# wl_phy_tx_secure register map
Vendor: Texas Instruments
Registers are 32-bit, access per field, reset 0x0 unless marked. A register's access mark holds for its fields unless they carry their own. Offsets are as the file gives them; [hi:lo] are bit positions; {n}, {i} and the like mark numbered series; <NAME> marks a mode.

## wl_phy_tx_secure (part 2 of 2)
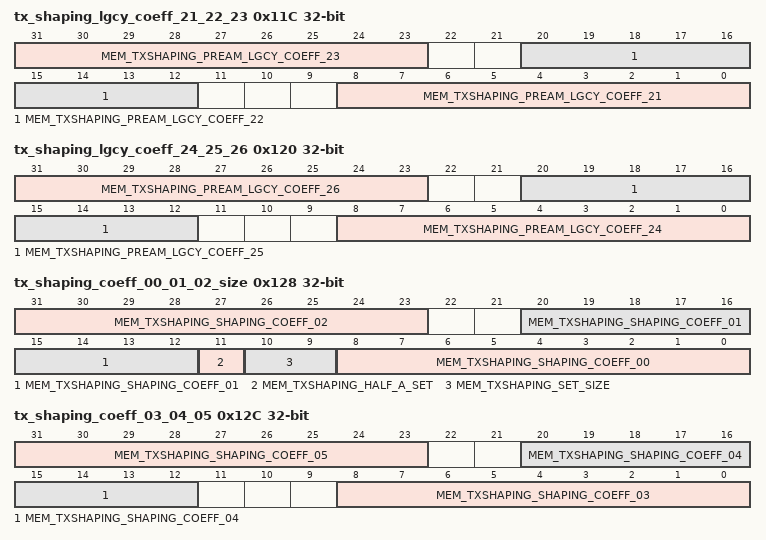
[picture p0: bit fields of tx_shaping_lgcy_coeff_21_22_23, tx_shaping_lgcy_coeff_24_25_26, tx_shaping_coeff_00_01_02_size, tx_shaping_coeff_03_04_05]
0x11C tx_shaping_lgcy_coeff_21_22_23 reset not defined — Part of the 28 coeffs for the legacy part of the preamble.
  [31:23] MEM_TXSHAPING_PREAM_LGCY_COEFF_23 rw — Part of the 28 coeffs for the legacy part of the preamble. <1.8u>
  [20:12] MEM_TXSHAPING_PREAM_LGCY_COEFF_22 rw — Part of the 28 coeffs for the legacy part of the preamble. <1.8u>
  [8:0] MEM_TXSHAPING_PREAM_LGCY_COEFF_21 rw — Part of the 28 coeffs for the legacy part of the preamble. <1.8u>
0x120 tx_shaping_lgcy_coeff_24_25_26 reset not defined — Part of the 28 coeffs for the legacy part of the preamble.
  [31:23] MEM_TXSHAPING_PREAM_LGCY_COEFF_26 rw — Part of the 28 coeffs for the legacy part of the preamble. <1.8u>
  [20:12] MEM_TXSHAPING_PREAM_LGCY_COEFF_25 rw — Part of the 28 coeffs for the legacy part of the preamble. <1.8u>
  [8:0] MEM_TXSHAPING_PREAM_LGCY_COEFF_24 rw — Part of the 28 coeffs for the legacy part of the preamble. <1.8u>
0x124 tx_shaping_lgcy_coeff_27 reset 0x27339 — Part of the 28 coeffs for the legacy part of the preamble.
  [8:0] MEM_TXSHAPING_PREAM_LGCY_COEFF_27 rw — Part of the 28 coeffs for the legacy part of the preamble. <1.8u>
0x128 tx_shaping_coeff_00_01_02_size — Part of the 62 coeffs for the shaping function. <1.8u>
  [31:23] MEM_TXSHAPING_SHAPING_COEFF_02 rw — Part of the 62 coeffs for the shaping function. <1.8u>
  [20:12] MEM_TXSHAPING_SHAPING_COEFF_01 rw — Part of the 62 coeffs for the shaping function. <1.8u>
  [11] MEM_TXSHAPING_HALF_A_SET rw — Half a Set option: 0: Disabled. 1: Enabled.
  [10:9] MEM_TXSHAPING_SET_SIZE rw — Set Size options: 0: 0 coefficients, Bypass Shaping module. 1: 18 coefficients. 2: 32 coefficients. 3: 62 coefficients.
  [8:0] MEM_TXSHAPING_SHAPING_COEFF_00 rw — Part of the 62 coeffs for the shaping function. <1.8u>
0x12C tx_shaping_coeff_03_04_05 — Part of the 62 coeffs for the shaping function. <1.8u>
  [31:23] MEM_TXSHAPING_SHAPING_COEFF_05 rw — Part of the 62 coeffs for the shaping function. <1.8u>
  [20:12] MEM_TXSHAPING_SHAPING_COEFF_04 rw — Part of the 62 coeffs for the shaping function. <1.8u>
  [8:0] MEM_TXSHAPING_SHAPING_COEFF_03 rw — Part of the 62 coeffs for the shaping function. <1.8u>
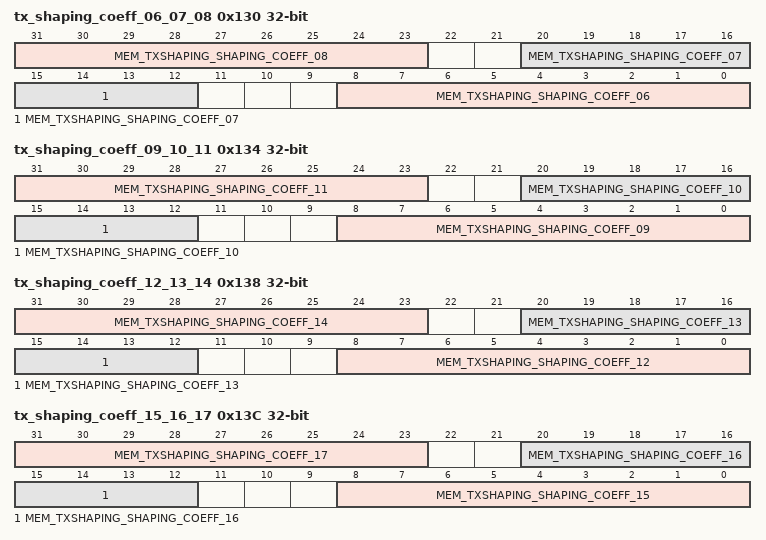
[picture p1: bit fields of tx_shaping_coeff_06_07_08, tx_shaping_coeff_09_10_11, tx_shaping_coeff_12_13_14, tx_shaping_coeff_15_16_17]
0x130 tx_shaping_coeff_06_07_08 — Part of the 62 coeffs for the shaping function. <1.8u>
  [31:23] MEM_TXSHAPING_SHAPING_COEFF_08 rw — Part of the 62 coeffs for the shaping function. <1.8u>
  [20:12] MEM_TXSHAPING_SHAPING_COEFF_07 rw — Part of the 62 coeffs for the shaping function. <1.8u>
  [8:0] MEM_TXSHAPING_SHAPING_COEFF_06 rw — Part of the 62 coeffs for the shaping function. <1.8u>
0x134 tx_shaping_coeff_09_10_11 — Part of the 62 coeffs for the shaping function. <1.8u>
  [31:23] MEM_TXSHAPING_SHAPING_COEFF_11 rw — Part of the 62 coeffs for the shaping function. <1.8u>
  [20:12] MEM_TXSHAPING_SHAPING_COEFF_10 rw — Part of the 62 coeffs for the shaping function. <1.8u>
  [8:0] MEM_TXSHAPING_SHAPING_COEFF_09 rw — Part of the 62 coeffs for the shaping function. <1.8u>
0x138 tx_shaping_coeff_12_13_14 — Part of the 62 coeffs for the shaping function. <1.8u>
  [31:23] MEM_TXSHAPING_SHAPING_COEFF_14 rw — Part of the 62 coeffs for the shaping function. <1.8u>
  [20:12] MEM_TXSHAPING_SHAPING_COEFF_13 rw — Part of the 62 coeffs for the shaping function. <1.8u>
  [8:0] MEM_TXSHAPING_SHAPING_COEFF_12 rw — Part of the 62 coeffs for the shaping function. <1.8u>
0x13C tx_shaping_coeff_15_16_17 — Part of the 62 coeffs for the shaping function. <1.8u>
  [31:23] MEM_TXSHAPING_SHAPING_COEFF_17 rw — Part of the 62 coeffs for the shaping function. <1.8u>
  [20:12] MEM_TXSHAPING_SHAPING_COEFF_16 rw — Part of the 62 coeffs for the shaping function. <1.8u>
  [8:0] MEM_TXSHAPING_SHAPING_COEFF_15 rw — Part of the 62 coeffs for the shaping function. <1.8u>
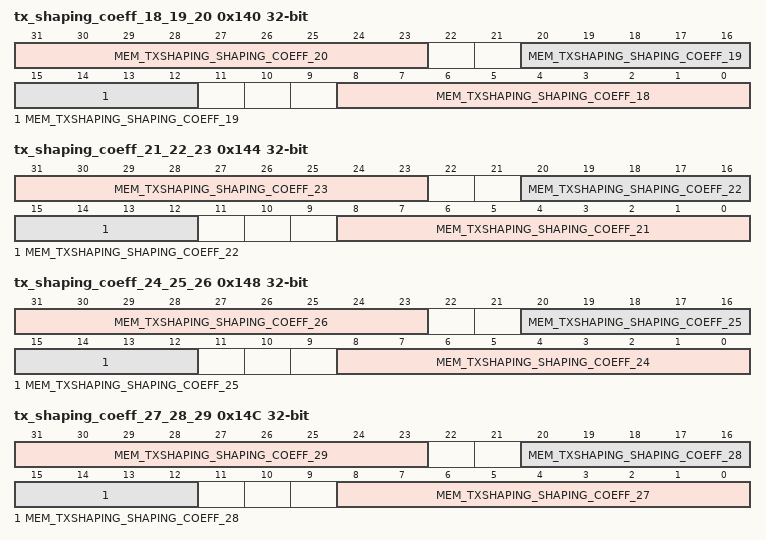
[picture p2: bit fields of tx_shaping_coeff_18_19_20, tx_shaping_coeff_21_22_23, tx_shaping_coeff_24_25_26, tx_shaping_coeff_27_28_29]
0x140 tx_shaping_coeff_18_19_20 — Part of the 62 coeffs for the shaping function. <1.8u>
  [31:23] MEM_TXSHAPING_SHAPING_COEFF_20 rw — Part of the 62 coeffs for the shaping function. <1.8u>
  [20:12] MEM_TXSHAPING_SHAPING_COEFF_19 rw — Part of the 62 coeffs for the shaping function. <1.8u>
  [8:0] MEM_TXSHAPING_SHAPING_COEFF_18 rw — Part of the 62 coeffs for the shaping function. <1.8u>
0x144 tx_shaping_coeff_21_22_23 — Part of the 62 coeffs for the shaping function. <1.8u>
  [31:23] MEM_TXSHAPING_SHAPING_COEFF_23 rw — Part of the 62 coeffs for the shaping function. <1.8u>
  [20:12] MEM_TXSHAPING_SHAPING_COEFF_22 rw — Part of the 62 coeffs for the shaping function. <1.8u>
  [8:0] MEM_TXSHAPING_SHAPING_COEFF_21 rw — Part of the 62 coeffs for the shaping function. <1.8u>
0x148 tx_shaping_coeff_24_25_26 — Part of the 62 coeffs for the shaping function. <1.8u>
  [31:23] MEM_TXSHAPING_SHAPING_COEFF_26 rw — Part of the 62 coeffs for the shaping function. <1.8u>
  [20:12] MEM_TXSHAPING_SHAPING_COEFF_25 rw — Part of the 62 coeffs for the shaping function. <1.8u>
  [8:0] MEM_TXSHAPING_SHAPING_COEFF_24 rw — Part of the 62 coeffs for the shaping function. <1.8u>
0x14C tx_shaping_coeff_27_28_29 — Part of the 62 coeffs for the shaping function. <1.8u>
  [31:23] MEM_TXSHAPING_SHAPING_COEFF_29 rw — Part of the 62 coeffs for the shaping function. <1.8u>
  [20:12] MEM_TXSHAPING_SHAPING_COEFF_28 rw — Part of the 62 coeffs for the shaping function. <1.8u>
  [8:0] MEM_TXSHAPING_SHAPING_COEFF_27 rw — Part of the 62 coeffs for the shaping function. <1.8u>
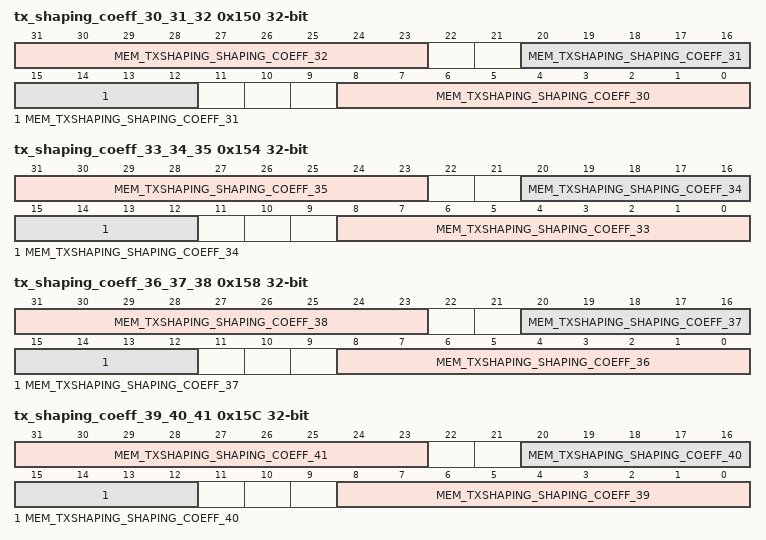
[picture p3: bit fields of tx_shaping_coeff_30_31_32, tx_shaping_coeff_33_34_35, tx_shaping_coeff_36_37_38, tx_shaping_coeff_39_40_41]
0x150 tx_shaping_coeff_30_31_32 — Part of the 62 coeffs for the shaping function. <1.8u>
  [31:23] MEM_TXSHAPING_SHAPING_COEFF_32 rw — Part of the 62 coeffs for the shaping function. <1.8u>
  [20:12] MEM_TXSHAPING_SHAPING_COEFF_31 rw — Part of the 62 coeffs for the shaping function. <1.8u>
  [8:0] MEM_TXSHAPING_SHAPING_COEFF_30 rw — Part of the 62 coeffs for the shaping function. <1.8u>
0x154 tx_shaping_coeff_33_34_35 — Part of the 62 coeffs for the shaping function. <1.8u>
  [31:23] MEM_TXSHAPING_SHAPING_COEFF_35 rw — Part of the 62 coeffs for the shaping function. <1.8u>
  [20:12] MEM_TXSHAPING_SHAPING_COEFF_34 rw — Part of the 62 coeffs for the shaping function. <1.8u>
  [8:0] MEM_TXSHAPING_SHAPING_COEFF_33 rw — Part of the 62 coeffs for the shaping function. <1.8u>
0x158 tx_shaping_coeff_36_37_38 — Part of the 62 coeffs for the shaping function. <1.8u>
  [31:23] MEM_TXSHAPING_SHAPING_COEFF_38 rw — Part of the 62 coeffs for the shaping function. <1.8u>
  [20:12] MEM_TXSHAPING_SHAPING_COEFF_37 rw — Part of the 62 coeffs for the shaping function. <1.8u>
  [8:0] MEM_TXSHAPING_SHAPING_COEFF_36 rw — Part of the 62 coeffs for the shaping function. <1.8u>
0x15C tx_shaping_coeff_39_40_41 — Part of the 62 coeffs for the shaping function. <1.8u>
  [31:23] MEM_TXSHAPING_SHAPING_COEFF_41 rw — Part of the 62 coeffs for the shaping function. <1.8u>
  [20:12] MEM_TXSHAPING_SHAPING_COEFF_40 rw — Part of the 62 coeffs for the shaping function. <1.8u>
  [8:0] MEM_TXSHAPING_SHAPING_COEFF_39 rw — Part of the 62 coeffs for the shaping function. <1.8u>
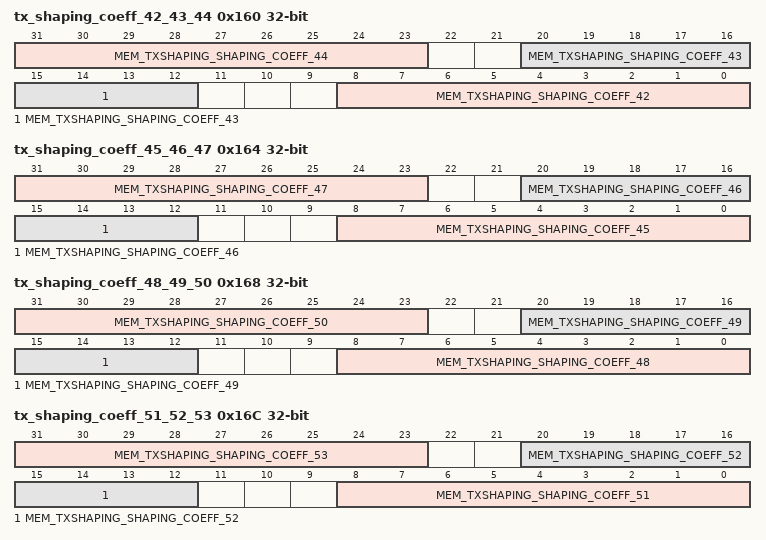
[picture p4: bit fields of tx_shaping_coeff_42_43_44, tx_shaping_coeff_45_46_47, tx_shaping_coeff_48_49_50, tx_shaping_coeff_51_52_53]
0x160 tx_shaping_coeff_42_43_44 — Part of the 62 coeffs for the shaping function. <1.8u>
  [31:23] MEM_TXSHAPING_SHAPING_COEFF_44 rw — Part of the 62 coeffs for the shaping function. <1.8u>
  [20:12] MEM_TXSHAPING_SHAPING_COEFF_43 rw — Part of the 62 coeffs for the shaping function. <1.8u>
  [8:0] MEM_TXSHAPING_SHAPING_COEFF_42 rw — Part of the 62 coeffs for the shaping function. <1.8u>
0x164 tx_shaping_coeff_45_46_47 — Part of the 62 coeffs for the shaping function. <1.8u>
  [31:23] MEM_TXSHAPING_SHAPING_COEFF_47 rw — Part of the 62 coeffs for the shaping function. <1.8u>
  [20:12] MEM_TXSHAPING_SHAPING_COEFF_46 rw — Part of the 62 coeffs for the shaping function. <1.8u>
  [8:0] MEM_TXSHAPING_SHAPING_COEFF_45 rw — Part of the 62 coeffs for the shaping function. <1.8u>
0x168 tx_shaping_coeff_48_49_50 — Part of the 62 coeffs for the shaping function. <1.8u>
  [31:23] MEM_TXSHAPING_SHAPING_COEFF_50 rw — Part of the 62 coeffs for the shaping function. <1.8u>
  [20:12] MEM_TXSHAPING_SHAPING_COEFF_49 rw — Part of the 62 coeffs for the shaping function. <1.8u>
  [8:0] MEM_TXSHAPING_SHAPING_COEFF_48 rw — Part of the 62 coeffs for the shaping function. <1.8u>
0x16C tx_shaping_coeff_51_52_53 — Part of the 62 coeffs for the shaping function. <1.8u>
  [31:23] MEM_TXSHAPING_SHAPING_COEFF_53 rw — Part of the 62 coeffs for the shaping function. <1.8u>
  [20:12] MEM_TXSHAPING_SHAPING_COEFF_52 rw — Part of the 62 coeffs for the shaping function. <1.8u>
  [8:0] MEM_TXSHAPING_SHAPING_COEFF_51 rw — Part of the 62 coeffs for the shaping function. <1.8u>
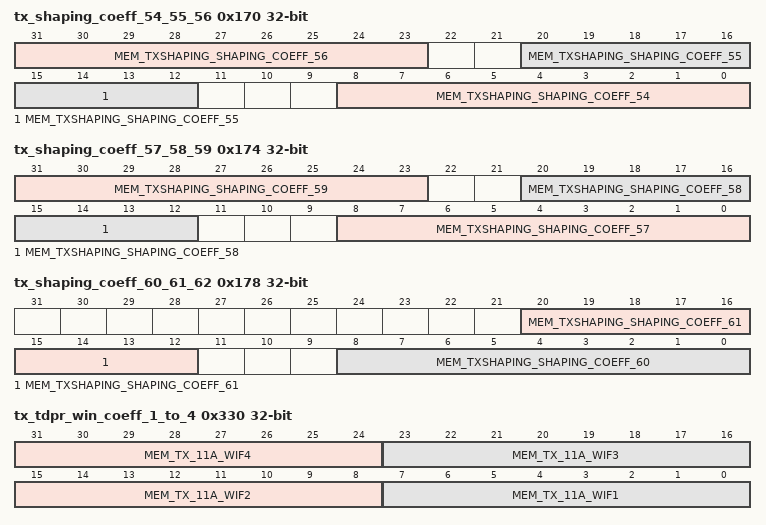
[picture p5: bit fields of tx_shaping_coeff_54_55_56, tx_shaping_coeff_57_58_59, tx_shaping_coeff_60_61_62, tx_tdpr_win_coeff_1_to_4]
0x170 tx_shaping_coeff_54_55_56 — Part of the 62 coeffs for the shaping function. <1.8u>
  [31:23] MEM_TXSHAPING_SHAPING_COEFF_56 rw — Part of the 62 coeffs for the shaping function. <1.8u>
  [20:12] MEM_TXSHAPING_SHAPING_COEFF_55 rw — Part of the 62 coeffs for the shaping function. <1.8u>
  [8:0] MEM_TXSHAPING_SHAPING_COEFF_54 rw — Part of the 62 coeffs for the shaping function. <1.8u>
0x174 tx_shaping_coeff_57_58_59 — Part of the 62 coeffs for the shaping function. <1.8u>
  [31:23] MEM_TXSHAPING_SHAPING_COEFF_59 rw — Part of the 62 coeffs for the shaping function. <1.8u>
  [20:12] MEM_TXSHAPING_SHAPING_COEFF_58 rw — Part of the 62 coeffs for the shaping function. <1.8u>
  [8:0] MEM_TXSHAPING_SHAPING_COEFF_57 rw — Part of the 62 coeffs for the shaping function. <1.8u>
0x178 tx_shaping_coeff_60_61_62 — Part of the 62 coeffs for the shaping function. <1.8u>
  [20:12] MEM_TXSHAPING_SHAPING_COEFF_61 rw — Part of the 62 coeffs for the shaping function. <1.8u>
  [8:0] MEM_TXSHAPING_SHAPING_COEFF_60 rw — Part of the 62 coeffs for the shaping function. <1.8u>
0x188 tx_tdpr_win_coeff_a reset 0x489 — The TDPR windowing coefficients. Each coefficient is 7 bits wide, unsigned. They are ordered in ramp-up order, i.e. starting from small (almost 0), to large (almost 128). 128 is not a valid value, and setting 0 also seems like a waste. The windowing coefficients are played in their order on the symbol being phased in, and in their reverse order on the symbol being phased out. The windowing_length field (TX_TDPR_CONFIG) sets the number of clk_80 sample coefficents to use for windowing. In case the length is smaller than 16, the ramp down starts with the last coefficient of the ramp-up, as dictated by the length. If you want to change the CSD, do it in the TX_TDPR_CSD_CTRL register.
  [6:0] MEM_WIN_COEFF_00 rw
0x330 tx_tdpr_win_coeff_1_to_4 rw reset not defined
  [31:24] MEM_TX_11A_WIF4 — TX_11A_WIF4 4th window factor when FIVE_WIN=='0'. 2nd window factor when FIVE_WIN=='1'.
  [23:16] MEM_TX_11A_WIF3 — TX_11A_WIF3 3rd Lowest window factor when FIVE_WIN=='0'. Lowest window factor when FIVE_WIN=='1'.
  [15:8] MEM_TX_11A_WIF2 — TX_11A_WIF2 2nd Lowest window factor when FIVE_WIN=='0'. Else - don't care.
  [7:0] MEM_TX_11A_WIF1 — TX_11A_WIF1 Lowest window factor when FIVE_WIN=='0'. Else - don't care
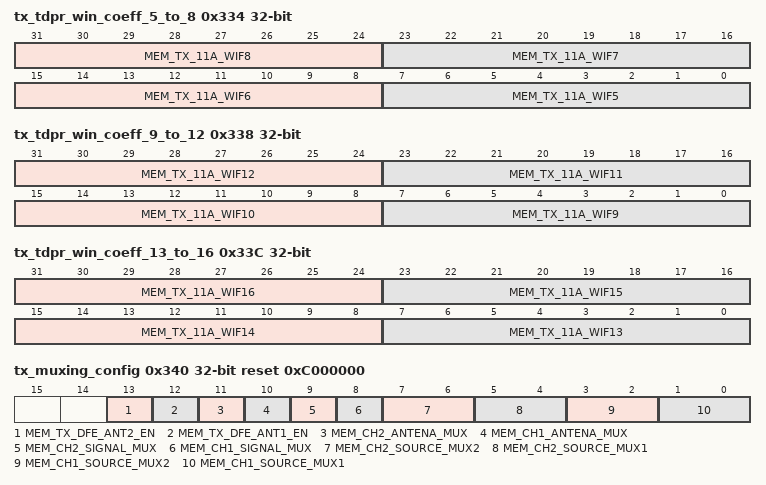
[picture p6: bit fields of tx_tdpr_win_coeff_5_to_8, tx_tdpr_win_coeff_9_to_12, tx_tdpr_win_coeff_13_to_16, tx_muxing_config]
0x334 tx_tdpr_win_coeff_5_to_8 rw reset not defined
  [31:24] MEM_TX_11A_WIF8 — TX_11A_WIF8 6th window factor when FIVE_WIN=='0'. 8th window factor when FIVE_WIN=='1'.
  [23:16] MEM_TX_11A_WIF7 — TX_11A_WIF7 7th window factor when FIVE_WIN=='0'. 5th window factor when FIVE_WIN=='1'.
  [15:8] MEM_TX_11A_WIF6 — TX_11A_WIF6 6th window factor when FIVE_WIN=='0'. 4th window factor when FIVE_WIN=='1'.
  [7:0] MEM_TX_11A_WIF5 — TX_11A_WIF5 5th window factor when FIVE_WIN=='0'. 3rd window factor when FIVE_WIN=='1'.
0x338 tx_tdpr_win_coeff_9_to_12 rw reset not defined
  [31:24] MEM_TX_11A_WIF12 — TX_11A_WIF8 6th window factor when FIVE_WIN=='0'. 8th window factor when FIVE_WIN=='1'.
  [23:16] MEM_TX_11A_WIF11 — TX_11A_WIF7 7th window factor when FIVE_WIN=='0'. 5th window factor when FIVE_WIN=='1'.
  [15:8] MEM_TX_11A_WIF10 — TX_11A_WIF6 6th window factor when FIVE_WIN=='0'. 4th window factor when FIVE_WIN=='1'.
  [7:0] MEM_TX_11A_WIF9 — TX_11A_WIF5 5th window factor when FIVE_WIN=='0'. 3rd window factor when FIVE_WIN=='1'.
0x33C tx_tdpr_win_coeff_13_to_16 rw reset not defined
  [31:24] MEM_TX_11A_WIF16 — TX_11A_WIF8 6th window factor when FIVE_WIN=='0'. 8th window factor when FIVE_WIN=='1'.
  [23:16] MEM_TX_11A_WIF15 — TX_11A_WIF7 7th window factor when FIVE_WIN=='0'. 5th window factor when FIVE_WIN=='1'.
  [15:8] MEM_TX_11A_WIF14 — TX_11A_WIF6 6th window factor when FIVE_WIN=='0'. 4th window factor when FIVE_WIN=='1'.
  [7:0] MEM_TX_11A_WIF13 — TX_11A_WIF5 5th window factor when FIVE_WIN=='0'. 3rd window factor when FIVE_WIN=='1'.
0x340 tx_muxing_config reset 0xC000000 (reset mask 0xFFFFC000) — Tx Mux - where OFDM/11b/Debug RAM/SigGen come together. This is the last mux before signal goes into DFE.
  [13] MEM_TX_DFE_ANT2_EN rw — Control over clocking and power over antenna2 in the Tx-DFE. 0 - Tx DFE Antenna2 is turned off 1 - Tx DFE Antenna2 is turned on The clocks that are directly gated according to this bit are clk_tx_ckvd_6_8_ant2 and clk_tx_ckvd_18_24_ant2. This bit is synchronized to ckvd_18_24 before being used to control the ckvd clocks. It's also used in order disable activity on both sides of the two resampler FIFOs (I & Q) in the antenna2 path.
  [12] MEM_TX_DFE_ANT1_EN rw — Control over clocking and power over antenna1 in the Tx-DFE. 0 - Tx DFE Antenna1 is turned off 1 - Tx DFE Antenna1 is turned on The clocks that are directly gated according to this bit are clk_tx_ckvd_6_8_ant1 and clk_tx_ckvd_18_24_ant1. This bit is synchronized to ckvd_18_24 before being used to control the ckvd clocks. It's also used in order disable activity on both sides of the two resampler FIFOs (I & Q) in the antenna1 path.
  [11] MEM_CH2_ANTENA_MUX rw — Antenna 2 connect to: 0 - Combined ch2 signal (Normal) 1 - Combined ch1 signal (Cross)
  [10] MEM_CH1_ANTENA_MUX rw — Antenna 1 connect to: 0 - Combined ch1 signal (Normal) 1 - Combined ch2 signal (Cross)
  [9] MEM_CH2_SIGNAL_MUX rw — 0 - Packet signal according A/B select 1 - No Signal
  [8] MEM_CH1_SIGNAL_MUX rw — 0 - Packet signal according A/B select 1 - No Signal
  [7:6] MEM_CH2_SOURCE_MUX2 rw — 0 - No Signal 1 - Signal coming from IQ Ram 2 - Signal coming from CW gen 3 - Signal coming from Modulator gen
  [5:4] MEM_CH2_SOURCE_MUX1 rw — 0 - No Signal 1 - Signal coming from IQ Ram 2 - Signal coming from CW gen 3 - Signal coming from Modulator gen
  [3:2] MEM_CH1_SOURCE_MUX2 rw — 0 - No Signal 1 - Signal coming from IQ Ram 2 - Signal coming from CW gen 3 - Signal coming from Modulator gen
  [1:0] MEM_CH1_SOURCE_MUX1 rw — 0 - No Signal 1 - Signal coming from IQ Ram 2 - Signal coming from CW gen 3 - Signal coming from Modulator gen
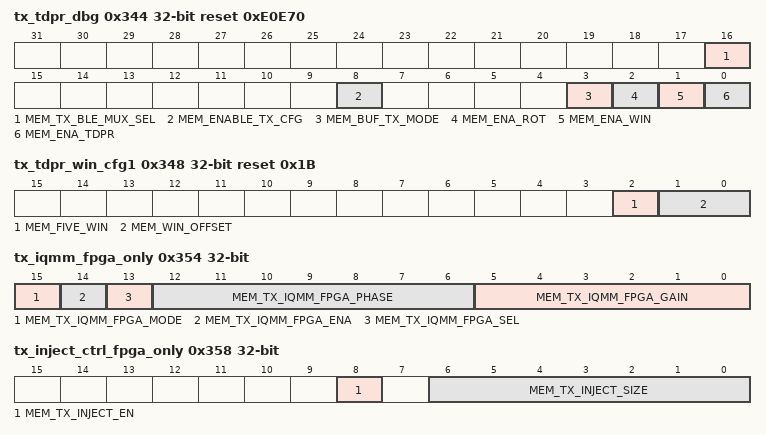
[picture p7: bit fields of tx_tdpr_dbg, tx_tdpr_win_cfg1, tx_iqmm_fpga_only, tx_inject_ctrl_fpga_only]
0x344 tx_tdpr_dbg reset 0xE0E70 (reset mask 0xFFFEFEF0)
  [16] MEM_TX_BLE_MUX_SEL rw — TX Resampler Input MUX select the BLE as input source - when set to '1'
  [8] MEM_ENABLE_TX_CFG rw — Use hard coded values for WIF coeffients instead of copied values from TX_CFG
  [3] MEM_BUF_TX_MODE rw — When '1', the TDPR will ignore the FDPR controls and read data from the IFFT buffer indicated by buffer_num. This is a special mode for where the time domain can be operated without passing through the frequency domain. When '0' regular operation mode
  [2] MEM_ENA_ROT rw — When '0' the rotator operation is being disabled (including flip and STF gain). When '1', the rotator operation is on.
  [1] MEM_ENA_WIN rw — When '0' the windowing operation is being disabled. When '1', the windowing operation is on.
  [0] MEM_ENA_TDPR rw — When '0', the TDPR block is bypassed. (TX is taken from rotator). when '1' the TDPR operates normaly.
0x348 tx_tdpr_win_cfg1 reset 0x1B (reset mask 0xFFFFFFFB)
  [2] MEM_FIVE_WIN rw — Five Windowing Factors '0' - Window contains 7 windowing factors '1' - Window contains 5 windowing factors
  [1:0] MEM_WIN_OFFSET rw — WIN_OFFSET Configure the location of the first sample of the window. '0' - First FFT address is 96 '1' - First FFT address is 95 '2' - First FFT address is 94 '3' - First FFT address is 93
0x354 tx_iqmm_fpga_only
  [15] MEM_TX_IQMM_FPGA_MODE rw — This control bit chooses a Tx-IQMM mode: 0 - IQ-Swap mode (like in TRIO) 1 - Signed-G mode; A new mode (Quattro only) It affects the way that the IQ_MM_CONST_SEL is used and the sign of the G correction factor.
  [14] MEM_TX_IQMM_FPGA_ENA rw — I/Q Mismatch Enable '0' - Bypass IQ Mismatch Module (default) '1' - Enable IQ Mismatch Module
  [13] MEM_TX_IQMM_FPGA_SEL rw — For this value to be relevant, the transmitter must be configured to receive coefficients from fixed registers (TX_CFG[12]=1, address 0x1000), and the IQ_MM_ENA bit must be set to one (TX_IQMM_CR[14]='1', this register). To choose between IQ-Swap mode and Signed-G mode, set IQ_MM_Mode bit[15]. In IQ-Swap Mode: I/Q Mismatch compensated channel selector. '0' - Compensate Q '1' - Compensate I. In Signed-G Mode: '0' - The gain correction value will be taken as positive, and subtracted from the I-channel path. '1' - The gain correction value will be taken as negative, and added to the I-channel path. Refrain from using negative zero (correct function not guaranteed).
  [12:6] MEM_TX_IQMM_FPGA_PHASE rw — I/Q Mismatch phase compensation. Signed 7 bit value (-64~+63). Avoid using -64 (correct function not guaranteed) in two's-complement format (there is a dedicated TC2SM conversion in HW; seems like a waste). For this value to be applied, the transmitter must be configured to receive coefficients from fixed registers (TX_CFG[12]=1, address 0x1000), and the IQ_MM_ENA bit must be set to one (TX_IQMM_CR[14]='1', this register).
  [5:0] MEM_TX_IQMM_FPGA_GAIN rw — I/Q Mismatch gain compensation. For this value to be applied, the transmitter must be configured to receive coefficients from fixed registers (TX_CFG[12]=1, address 0x1000), and the IQ_MM_ENA bit must be set to one (TX_IQMM_CR[14]='1', this register). To choose between IQ-Swap mode and Signed-G mode, set IQ_MM_Mode bit[15]. IQ-Swap Mode Unsigned 6 bit value (0~+63) Signed-G Mode Unsigned 6 bit value (0~+63). Set the sign bit in IQ_MM_CONST_SEL bit[13]. Note that if you were to concatenate the sign bit to the IQ_MM_CONST_G field, the resulting format would be sign-magnitude, not two's-complement. That's in contrast to the P factor, which is always signed, and in two's-complement format. Refrain from using negative zero (correct function not guaranteed).
0x358 tx_inject_ctrl_fpga_only
  [8] MEM_TX_INJECT_EN rw
  [6:0] MEM_TX_INJECT_SIZE rw — Size of Inject Mem: Up to 128 sample (value of 127) at 80MJz
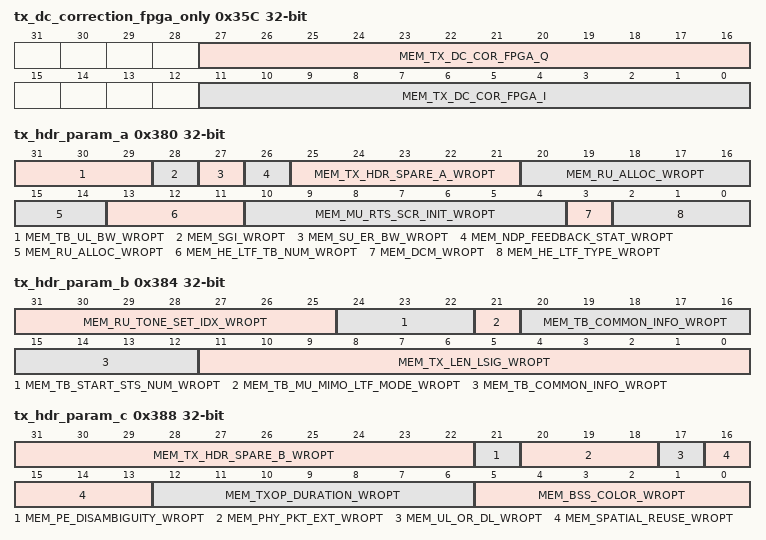
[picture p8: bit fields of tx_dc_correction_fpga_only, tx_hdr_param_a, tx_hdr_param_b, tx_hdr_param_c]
0x35C tx_dc_correction_fpga_only
  [27:16] MEM_TX_DC_COR_FPGA_Q rw — Tx DC Correction - Ch Q
  [11:0] MEM_TX_DC_COR_FPGA_I rw — Tx DC Correction - Ch I
0x360 tx_fpga_spare_reg_0
  [15:0] MEM_TX_SPARE_REG_0 rw
0x364 tx_fpga_spare_reg_1
  [15:0] MEM_TX_SPARE_REG_1 rw
0x368 tx_dig_gain_fpga_only reset 0x8080
  [7:0] MEM_TX_DIG_GAIN rw — Tx Digital Gain for FPGA The Gain is linear in range of up to gain of 2 the Gain is <1.7uns> gain ~2 ( 3dBm) - 0xFF gain 1 ( 0dBm) - 0x80 (default) gain 0.5 (-3dBm) - 0x40
0x380 tx_hdr_param_a rw — TX Header S/W RD-WR. (Note: Must be read-modufy-write)
  [31:29] MEM_TB_UL_BW_WROPT, [28] MEM_SGI_WROPT, [27] MEM_SU_ER_BW_WROPT, [26] MEM_NDP_FEEDBACK_STAT_WROPT, [25:21] MEM_TX_HDR_SPARE_A_WROPT, [20:14] MEM_RU_ALLOC_WROPT, [13:11] MEM_HE_LTF_TB_NUM_WROPT, [10:4] MEM_MU_RTS_SCR_INIT_WROPT, [3] MEM_DCM_WROPT, [2:0] MEM_HE_LTF_TYPE_WROPT
0x384 tx_hdr_param_b rw — TX Header S/W RD-WR.
  [31:25] MEM_RU_TONE_SET_IDX_WROPT, [24:22] MEM_TB_START_STS_NUM_WROPT, [21] MEM_TB_MU_MIMO_LTF_MODE_WROPT, [20:12] MEM_TB_COMMON_INFO_WROPT, [11:0] MEM_TX_LEN_LSIG_WROPT
0x388 tx_hdr_param_c rw — TX Header S/W RD-WR. (Note: Must be read-modufy-write)
  [31:22] MEM_TX_HDR_SPARE_B_WROPT, [21] MEM_PE_DISAMBIGUITY_WROPT, [20:18] MEM_PHY_PKT_EXT_WROPT, [17] MEM_UL_OR_DL_WROPT, [16:13] MEM_SPATIAL_REUSE_WROPT, [12:6] MEM_TXOP_DURATION_WROPT, [5:0] MEM_BSS_COLOR_WROPT
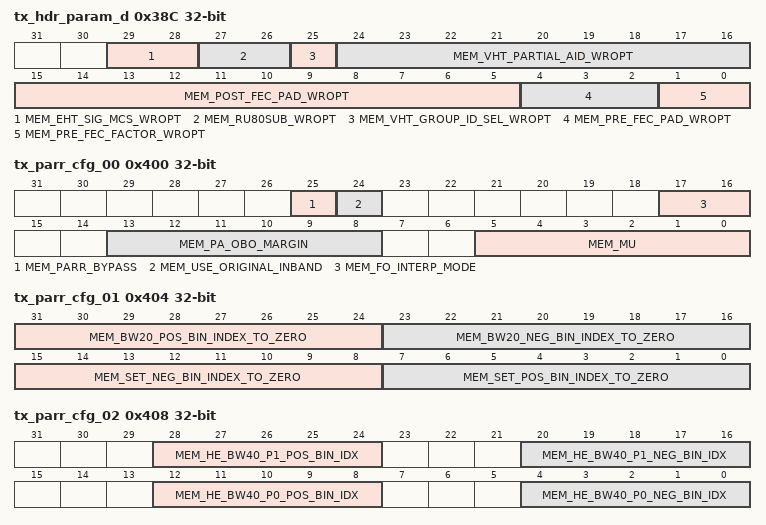
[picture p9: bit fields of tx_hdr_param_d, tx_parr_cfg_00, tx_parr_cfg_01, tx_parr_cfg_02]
0x38C tx_hdr_param_d — TX Header S/W RD-WR.
  [29:28] MEM_EHT_SIG_MCS_WROPT rw, [27:26] MEM_RU80SUB_WROPT rw, [25] MEM_VHT_GROUP_ID_SEL_WROPT rw, [24:16] MEM_VHT_PARTIAL_AID_WROPT rw, [15:5] MEM_POST_FEC_PAD_WROPT rw, [4:2] MEM_PRE_FEC_PAD_WROPT rw, [1:0] MEM_PRE_FEC_FACTOR_WROPT rw
0x390 tx_hdr_param_e — TX Header S/W RD-WR.
  [10:0] MEM_STA_ID_WROPT rw
0x398 tx_hdr_param_ovr rw — TX Header S/W RD-WR.
  [31:0] MEM_HDR_PARAM_OVR
0x400 tx_parr_cfg_00 reset not defined
  [25] MEM_PARR_BYPASS rw — Bypass Parr reduction
  [24] MEM_USE_ORIGINAL_INBAND rw — Choose whether to replace the in-band bins with the originals that were in the PARR input (good for high rates requiring good EVM) or to use the processed in-band bins (good for mask limited rates with lenient EVM requirements) 0x0 -Use clipped IB bins 0x1 -Use original IB bins
  [17:16] MEM_FO_INTERP_MODE rw — Interpolation mode for far-off mask (FD Clipping block) 0x0: None -W/G zeroed out 0x1: x8 0x2: x16 0x3: x32
  [13:8] MEM_PA_OBO_MARGIN rw — Time domain clipping thresholds extra margin from target PA OBO (in dB scale) <3.3s>
  [5:0] MEM_MU rw — Time domain clipping factor of pushing-back any sample that is above the clipping threshold. <2.4u>
0x404 tx_parr_cfg_01 rw reset not defined
  [31:24] MEM_BW20_POS_BIN_INDEX_TO_ZERO — 20MHz HE/Non-HE transmission bin to zero out regrowth (0 + BIN_IDX)
  [23:16] MEM_BW20_NEG_BIN_INDEX_TO_ZERO — 20MHz HE/Non-HE transmission bin to zero out regrowth (0 + BIN_IDX)
  [15:8] MEM_SET_NEG_BIN_INDEX_TO_ZERO — Negative bin indexes (in absolute value) above this value will be set to 0. 255 -all OOB negative bins (except bin -256 [or bin -64 when FFT = 128]) will be gained and clipped and appear at the output 108 -All OOB negative bins will be zeroed out 0 -This field is overridden by the value
  [7:0] MEM_SET_POS_BIN_INDEX_TO_ZERO — Positive bin indexes above this value will be set to 0. 255 -all OOB positive bins will be gained and clipped and appear at the output 108 -All OOB positive bins will be zeroed out 0 -This field is overridden by the value selected from BW20_BIN_TO_ZERO (POS_BIN field) and HE_TB_POS_BIN_TO_ZERO
0x408 tx_parr_cfg_02 reset not defined
  [28:24] MEM_HE_BW40_P1_POS_BIN_IDX rw — HE_TB PPDU 40MHz/80MHz with different primary index, positive bin index from which to zero out the OOB bins regrowth (108 + BIN_IDX). Affects only when POS_BIN_IDX_TO_ZERO is 0x0. Value 0x1F means no limit.
  [20:16] MEM_HE_BW40_P1_NEG_BIN_IDX rw — HE_TB PPDU 40MHz/80MHz with different primary index, negative bin index from which to zero out the OOB bins regrowth (-108 - BIN_IDX). Affects only when NEG_BIN_IDX_TO_ZERO is 0x0. Value 0x1F means no limit.
  [12:8] MEM_HE_BW40_P0_POS_BIN_IDX rw — HE_TB PPDU 40MHz/80MHz with different primary index, positive bin index from which to zero out the OOB bins regrowth (108 + BIN_IDX). Affects only when POS_BIN_IDX_TO_ZERO is 0x0. Value 0x1F means no limit.
  [4:0] MEM_HE_BW40_P0_NEG_BIN_IDX rw — HE_TB PPDU 40MHz/80MHz with different primary index, negative bin index from which to zero out the OOB bins regrowth (-108 - BIN_IDX). Affects only when NEG_BIN_IDX_TO_ZERO is 0x0. Value 0x1F means no limit.
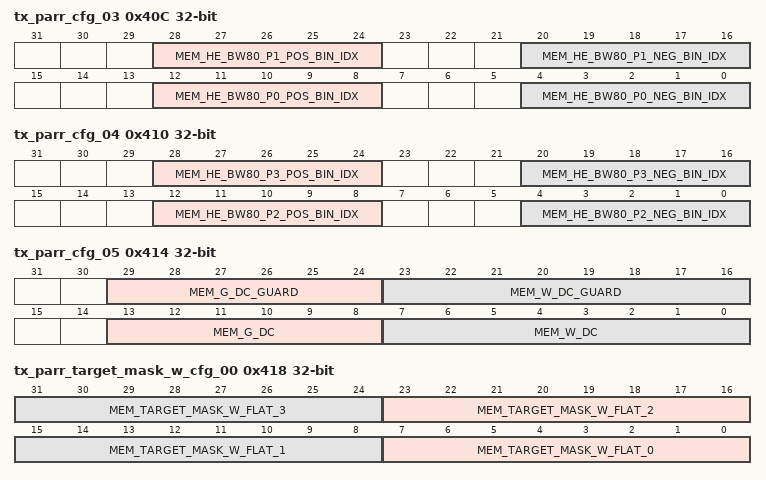
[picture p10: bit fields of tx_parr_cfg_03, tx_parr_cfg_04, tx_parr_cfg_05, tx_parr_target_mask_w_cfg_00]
0x40C tx_parr_cfg_03 reset not defined
  [28:24] MEM_HE_BW80_P1_POS_BIN_IDX rw — HE_TB PPDU 40MHz/80MHz with different primary index, positive bin index from which to zero out the OOB bins regrowth (108 + BIN_IDX). Affects only when POS_BIN_IDX_TO_ZERO is 0x0. Value 0x1F means no limit.
  [20:16] MEM_HE_BW80_P1_NEG_BIN_IDX rw — HE_TB PPDU 40MHz/80MHz with different primary index, negative bin index from which to zero out the OOB bins regrowth (-108 - BIN_IDX). Affects only when NEG_BIN_IDX_TO_ZERO is 0x0. Value 0x1F means no limit.
  [12:8] MEM_HE_BW80_P0_POS_BIN_IDX rw — HE_TB PPDU 40MHz/80MHz with different primary index, positive bin index from which to zero out the OOB bins regrowth (108 + BIN_IDX). Affects only when POS_BIN_IDX_TO_ZERO is 0x0. Value 0x1F means no limit.
  [4:0] MEM_HE_BW80_P0_NEG_BIN_IDX rw — HE_TB PPDU 40MHz/80MHz with different primary index, negative bin index from which to zero out the OOB bins regrowth (-108 - BIN_IDX). Affects only when NEG_BIN_IDX_TO_ZERO is 0x0. Value 0x1F means no limit.
0x410 tx_parr_cfg_04 reset not defined
  [28:24] MEM_HE_BW80_P3_POS_BIN_IDX rw — HE_TB PPDU 40MHz/80MHz with different primary index, positive bin index from which to zero out the OOB bins regrowth (108 + BIN_IDX). Affects only when POS_BIN_IDX_TO_ZERO is 0x0. Value 0x1F means no limit.
  [20:16] MEM_HE_BW80_P3_NEG_BIN_IDX rw — HE_TB PPDU 40MHz/80MHz with different primary index, negative bin index from which to zero out the OOB bins regrowth (-108 - BIN_IDX). Affects only when NEG_BIN_IDX_TO_ZERO is 0x0. Value 0x1F means no limit.
  [12:8] MEM_HE_BW80_P2_POS_BIN_IDX rw — HE_TB PPDU 40MHz/80MHz with different primary index, positive bin index from which to zero out the OOB bins regrowth (108 + BIN_IDX). Affects only when POS_BIN_IDX_TO_ZERO is 0x0. Value 0x1F means no limit.
  [4:0] MEM_HE_BW80_P2_NEG_BIN_IDX rw — HE_TB PPDU 40MHz/80MHz with different primary index, negative bin index from which to zero out the OOB bins regrowth (-108 - BIN_IDX). Affects only when NEG_BIN_IDX_TO_ZERO is 0x0. Value 0x1F means no limit.
0x414 tx_parr_cfg_05 reset not defined
  [29:24] MEM_G_DC_GUARD rw, [23:16] MEM_W_DC_GUARD rw, [13:8] MEM_G_DC rw, [7:0] MEM_W_DC rw
0x418 tx_parr_target_mask_w_cfg_00 rw reset not defined
  [8n+7:8n] MEM_TARGET_MASK_W_FLAT_{n} (n=0..3)
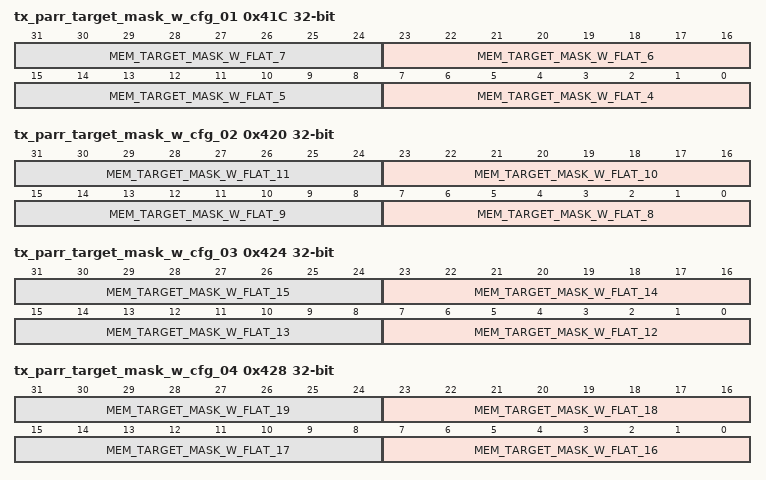
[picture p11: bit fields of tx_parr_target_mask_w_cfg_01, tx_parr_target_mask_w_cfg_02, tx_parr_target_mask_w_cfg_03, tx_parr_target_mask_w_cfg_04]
0x41C tx_parr_target_mask_w_cfg_01 rw reset not defined
  [8n-25:8n-32] MEM_TARGET_MASK_W_FLAT_{n} (n=4..7)
0x420 tx_parr_target_mask_w_cfg_02 rw reset not defined
  [8n-57:8n-64] MEM_TARGET_MASK_W_FLAT_{n} (n=8..11)
0x424 tx_parr_target_mask_w_cfg_03 rw reset not defined
  [8n-89:8n-96] MEM_TARGET_MASK_W_FLAT_{n} (n=12..15)
0x428 tx_parr_target_mask_w_cfg_04 rw reset not defined
  [8n-121:8n-128] MEM_TARGET_MASK_W_FLAT_{n} (n=16..19)
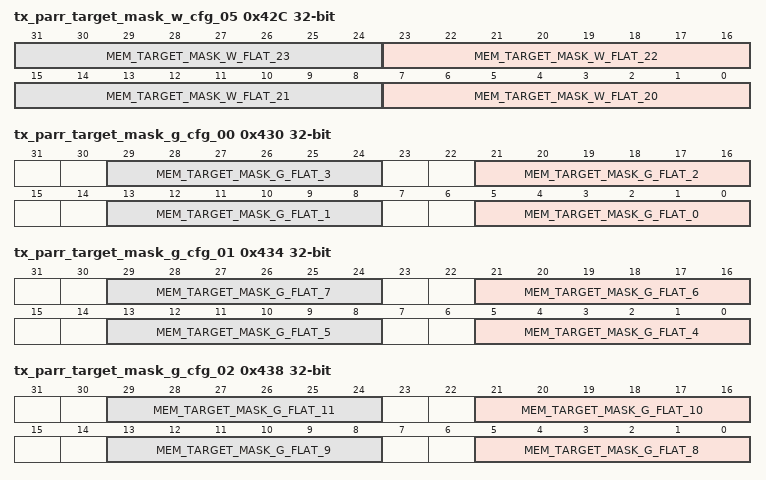
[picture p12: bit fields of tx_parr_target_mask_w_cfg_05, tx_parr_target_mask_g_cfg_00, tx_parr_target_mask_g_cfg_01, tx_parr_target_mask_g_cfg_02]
0x42C tx_parr_target_mask_w_cfg_05 rw reset not defined
  [8n-153:8n-160] MEM_TARGET_MASK_W_FLAT_{n} (n=20..23)
0x430 tx_parr_target_mask_g_cfg_00 reset not defined
  [8n+5:8n] MEM_TARGET_MASK_G_FLAT_{n} rw (n=0..3)
0x434 tx_parr_target_mask_g_cfg_01 reset not defined
  [8n-27:8n-32] MEM_TARGET_MASK_G_FLAT_{n} rw (n=4..7)
0x438 tx_parr_target_mask_g_cfg_02 reset not defined
  [8n-59:8n-64] MEM_TARGET_MASK_G_FLAT_{n} rw (n=8..11)
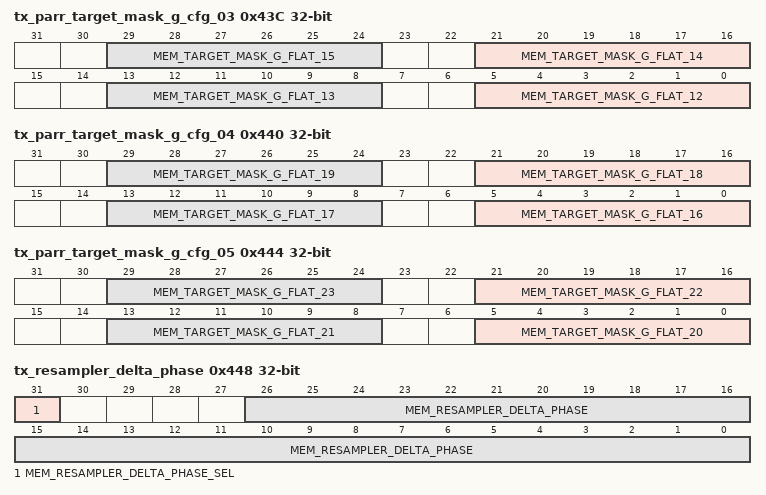
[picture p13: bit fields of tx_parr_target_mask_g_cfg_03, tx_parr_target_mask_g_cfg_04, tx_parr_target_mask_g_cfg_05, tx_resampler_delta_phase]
0x43C tx_parr_target_mask_g_cfg_03 reset not defined
  [8n-91:8n-96] MEM_TARGET_MASK_G_FLAT_{n} rw (n=12..15)
0x440 tx_parr_target_mask_g_cfg_04 reset not defined
  [8n-123:8n-128] MEM_TARGET_MASK_G_FLAT_{n} rw (n=16..19)
0x444 tx_parr_target_mask_g_cfg_05 reset not defined
  [8n-155:8n-160] MEM_TARGET_MASK_G_FLAT_{n} rw (n=20..23)
0x448 tx_resampler_delta_phase
  [31] MEM_RESAMPLER_DELTA_PHASE_SEL rw — When set to '1' Select the MEM_RESAMPLER_DELTA_PHASE MMR as input to the RESAMPLER DELTA PHASE. Otherwise use wl_phy_pllrelock_tx_resampler_ratio_out.
  [26:0] MEM_RESAMPLER_DELTA_PHASE rw
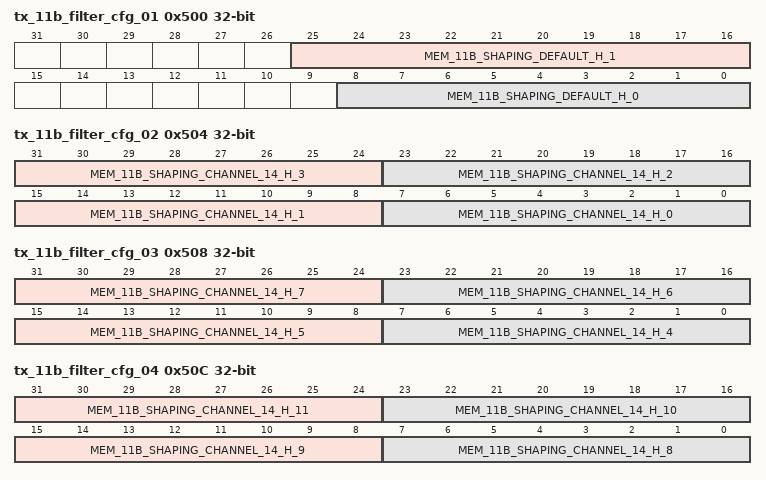
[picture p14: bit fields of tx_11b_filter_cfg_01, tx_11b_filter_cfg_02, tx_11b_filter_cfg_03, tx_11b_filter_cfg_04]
0x500 tx_11b_filter_cfg_01 reset not defined
  [25:16] MEM_11B_SHAPING_DEFAULT_H_1 rw — second coeffincient for non channel 14 <1.9u> - Default 585
  [8:0] MEM_11B_SHAPING_DEFAULT_H_0 rw — first coeffincient for non channel 14 <0.9u> - Default 302
0x504 tx_11b_filter_cfg_02 rw reset not defined
  [31:24] MEM_11B_SHAPING_CHANNEL_14_H_3 — coeffincient 3 for channel 14 filter <-1.9s> - Default 0
  [23:16] MEM_11B_SHAPING_CHANNEL_14_H_2 — coeffincient 2 for channel 14 filter <-1.9s> - Default -1
  [15:8] MEM_11B_SHAPING_CHANNEL_14_H_1 — coeffincient 1 for channel 14 filter <-1.9s> - Default 0
  [7:0] MEM_11B_SHAPING_CHANNEL_14_H_0 — coeffincient 0 for channel 14 filter <-1.9s> - Default 0
0x508 tx_11b_filter_cfg_03 rw reset not defined
  [31:24] MEM_11B_SHAPING_CHANNEL_14_H_7 — coeffincient 7 for channel 14 filter <-1.9s> - Default -4
  [23:16] MEM_11B_SHAPING_CHANNEL_14_H_6 — coeffincient 6 for channel 14 filter <-1.9s> - Default 10
  [15:8] MEM_11B_SHAPING_CHANNEL_14_H_5 — coeffincient 5 for channel 14 filter <-1.9s> - Default -3
  [7:0] MEM_11B_SHAPING_CHANNEL_14_H_4 — coeffincient 4 for channel 14 filter <-1.9s> - Default -3
0x50C tx_11b_filter_cfg_04 rw reset not defined
  [31:24] MEM_11B_SHAPING_CHANNEL_14_H_11 — coeffincient 11 for channel 14 filter <-1.9s> - Default 8
  [23:16] MEM_11B_SHAPING_CHANNEL_14_H_10 — coeffincient 10 for channel 14 filter <-1.9s> - Default 69
  [15:8] MEM_11B_SHAPING_CHANNEL_14_H_9 — coeffincient 9 for channel 14 filter <-1.9s> - Default 6
  [7:0] MEM_11B_SHAPING_CHANNEL_14_H_8 — coeffincient 8 for channel 14 filter <-1.9s> - Default -33
0x510 tx_11b_filter_cfg_05 reset not defined
  [30:20] MEM_11B_SHAPING_CHANNEL_14_H_14 rw — coeffincient 14 for channel 14 filter <2.9s> - Default 616
  [18:8] MEM_11B_SHAPING_CHANNEL_14_H_13 rw — coeffincient 13 for channel 14 filter <2.9s> - Default 221
  [7:0] MEM_11B_SHAPING_CHANNEL_14_H_12 rw — coeffincient 12 for channel 14 filter <-1.9s> - Default -41
0x514 tx_11b_filter_cfg_06 reset 0x3
  [0] MEM_11B_CHANNEL_14_FLAG rw — 11B shapping Filter select: 0 - non channel 14 (Interp by 2 to 22M) - Default 1 - channel 14 (Interp by 3 to 33M)
0x600 tx_inject_mem_fpga_only rw
  [31:0] MEM_TX_INJECT_MEM_7FC_WRMEMP — The FPGA Inject memory, up to 128 sample at 80M I [11: 0] Q [27:16]
